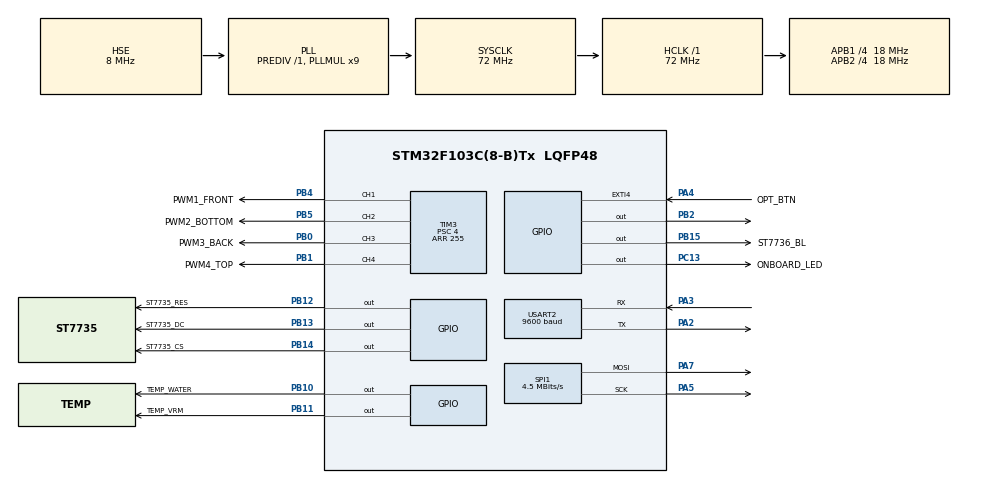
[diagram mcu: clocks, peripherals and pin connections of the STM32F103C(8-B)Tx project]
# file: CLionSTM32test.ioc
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Dma.Request0=SPI1_TX
Dma.SPI1_TX.0.Direction=DMA_MEMORY_TO_PERIPH
Dma.SPI1_TX.0.Instance=DMA1_Channel3
Dma.SPI1_TX.0.MemDataAlignment=DMA_MDATAALIGN_BYTE
Dma.SPI1_TX.0.MemInc=DMA_MINC_ENABLE
Dma.SPI1_TX.0.Mode=DMA_NORMAL
Dma.SPI1_TX.0.PeriphDataAlignment=DMA_PDATAALIGN_BYTE
Dma.SPI1_TX.0.PeriphInc=DMA_PINC_DISABLE
Dma.SPI1_TX.0.Priority=DMA_PRIORITY_LOW
Mcu.Family=STM32F1
Mcu.Name=STM32F103C(8-B)Tx
Mcu.Package=LQFP48
NVIC.DMA1_Channel3_IRQn=true\:0\:0\:false\:false\:true\:false\:true
NVIC.EXTI4_IRQn=true\:0\:0\:false\:false\:true\:true\:true
NVIC.PriorityGroup=NVIC_PRIORITYGROUP_4
NVIC.USART2_IRQn=true\:0\:0\:false\:false\:true\:true\:true
PA13.Mode=Serial_Wire
PA13.Signal=SYS_JTMS-SWDIO
PA14.Mode=Serial_Wire
PA14.Signal=SYS_JTCK-SWCLK
PA2.Mode=Asynchronous
PA2.Signal=USART2_TX
PA3.Mode=Asynchronous
PA3.Signal=USART2_RX
PA4.GPIO_Label=OPT_BTN
PA4.Signal=GPXTI4
PA5.Mode=TX_Only_Simplex_Unidirect_Master
PA5.Signal=SPI1_SCK
PA7.Mode=TX_Only_Simplex_Unidirect_Master
PA7.Signal=SPI1_MOSI
PB0.GPIO_Label=PWM3_BACK
PB0.GPIO_Speed=GPIO_SPEED_FREQ_HIGH
PB0.Signal=S_TIM3_CH3
PB1.GPIO_Label=PWM4_TOP
PB1.GPIO_Speed=GPIO_SPEED_FREQ_HIGH
PB1.Signal=S_TIM3_CH4
PB10.GPIO_Label=TEMP_WATER
PB10.Signal=GPIO_Output
PB11.GPIO_Label=TEMP_VRM
PB11.Signal=GPIO_Output
PB12.GPIO_Label=ST7735_RES
PB12.Signal=GPIO_Output
PB13.GPIO_Label=ST7735_DC
PB13.Signal=GPIO_Output
PB14.GPIO_Label=ST7735_CS
PB14.Signal=GPIO_Output
PB15.GPIO_Label=ST7736_BL
PB15.Signal=GPIO_Output
PB2.Signal=GPIO_Output
PB4.GPIO_Label=PWM1_FRONT
PB4.GPIO_Speed=GPIO_SPEED_FREQ_HIGH
PB4.Signal=S_TIM3_CH1
PB5.GPIO_Label=PWM2_BOTTOM
PB5.GPIO_Speed=GPIO_SPEED_FREQ_HIGH
PB5.Signal=S_TIM3_CH2
PC13-TAMPER-RTC.GPIO_Label=ONBOARD_LED
PC13-TAMPER-RTC.Signal=GPIO_Output
PD0-OSC_IN.Mode=HSE-External-Oscillator
PD0-OSC_IN.Signal=RCC_OSC_IN
PD1-OSC_OUT.Mode=HSE-External-Oscillator
PD1-OSC_OUT.Signal=RCC_OSC_OUT
ProjectManager.HeapSize=0x200
ProjectManager.StackSize=0x400
ProjectManager.TargetToolchain=SW4STM32
RCC.AHBFreq_Value=72000000
RCC.APB1CLKDivider=RCC_HCLK_DIV4
RCC.APB1Freq_Value=18000000
RCC.APB1TimFreq_Value=36000000
RCC.APB2CLKDivider=RCC_HCLK_DIV4
RCC.APB2Freq_Value=18000000
RCC.APB2TimFreq_Value=36000000
RCC.HCLKFreq_Value=72000000
RCC.PLLMUL=RCC_PLL_MUL9
RCC.PLLSourceVirtual=RCC_PLLSOURCE_HSE
RCC.SYSCLKFreq_VALUE=72000000
RCC.SYSCLKSource=RCC_SYSCLKSOURCE_PLLCLK
RCC.USBFreq_Value=72000000
SH.S_TIM3_CH1.0=TIM3_CH1,PWM Generation1 CH1
SH.S_TIM3_CH2.0=TIM3_CH2,PWM Generation2 CH2
SH.S_TIM3_CH3.0=TIM3_CH3,PWM Generation3 CH3
SH.S_TIM3_CH4.0=TIM3_CH4,PWM Generation4 CH4
SPI1.BaudRatePrescaler=SPI_BAUDRATEPRESCALER_4
SPI1.CalculateBaudRate=4.5 MBits/s
SPI1.Direction=SPI_DIRECTION_2LINES
SPI1.Mode=SPI_MODE_MASTER
SPI1.VirtualType=VM_MASTER
TIM3.Channel-PWM\ Generation1\ CH1=TIM_CHANNEL_1
TIM3.Channel-PWM\ Generation2\ CH2=TIM_CHANNEL_2
TIM3.Channel-PWM\ Generation3\ CH3=TIM_CHANNEL_3
TIM3.Channel-PWM\ Generation4\ CH4=TIM_CHANNEL_4
TIM3.Period=255
TIM3.Prescaler=4
USART2.BaudRate=9600
USART2.VirtualMode=VM_ASYNC
VP_TIM3_VS_ClockSourceINT.Mode=Internal
board=custom

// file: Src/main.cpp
/* USER CODE BEGIN Header */
/**
  ******************************************************************************
  * @file           : main.c
  * @brief          : Main program body
  ******************************************************************************
  * @attention
  *
  * <h2><center>&copy; Copyright (c) 2020 STMicroelectronics.
  * All rights reserved.</center></h2>
  *
  * This software component is licensed by ST under BSD 3-Clause license,
  * the "License"; You may not use this file except in compliance with the
  * License. You may obtain a copy of the License at:
  *                        opensource.org/licenses/BSD-3-Clause
  *
  ******************************************************************************
  */
/* USER CODE END Header */

#include "main.h"

/* USER CODE BEGIN Includes */
#include "cpp/Orchestrator.cpp"
/* USER CODE END Includes */

/* USER CODE BEGIN PTD */
#pragma clang diagnostic push
#pragma ide diagnostic ignored "EndlessLoop"
/* USER CODE END PTD */

SPI_HandleTypeDef hspi1;
DMA_HandleTypeDef hdma_spi1_tx;

TIM_HandleTypeDef htim3;

UART_HandleTypeDef huart2;

void SystemClock_Config(void);
static void MX_GPIO_Init(void);
static void MX_DMA_Init(void);
static void MX_SPI1_Init(void);
static void MX_USART2_UART_Init(void);
static void MX_TIM3_Init(void);

int main(void)
{

  /* MCU Configuration--------------------------------------------------------*/

  /* Reset of all peripherals, Initializes the Flash interface and the Systick. */
  HAL_Init();

  /* Configure the system clock */
  SystemClock_Config();

  /* Initialize all configured peripherals */
  MX_GPIO_Init();
  MX_DMA_Init();
  MX_SPI1_Init();
  MX_USART2_UART_Init();
  MX_TIM3_Init();
  /* USER CODE BEGIN 2 */
  HAL_TIM_Base_Start_IT(&htim3); // start timer
  HAL_TIM_PWM_Start(&htim3, TIM_CHANNEL_1);
  HAL_TIM_PWM_Start(&htim3, TIM_CHANNEL_2);
  HAL_TIM_PWM_Start(&htim3, TIM_CHANNEL_3);
  HAL_TIM_PWM_Start(&htim3, TIM_CHANNEL_4);

  Orchestrator orchestrator = Orchestrator(&huart2);
  /* USER CODE END 2 */

  /* Infinite loop */
  /* USER CODE BEGIN WHILE */
  while (true)
  {
    orchestrator.loop();
    /* USER CODE END WHILE */

  }
}

void SystemClock_Config(void)
{
  RCC_OscInitTypeDef RCC_OscInitStruct = {0};
  RCC_ClkInitTypeDef RCC_ClkInitStruct = {0};

  /** Initializes the CPU, AHB and APB busses clocks
  */
  RCC_OscInitStruct.OscillatorType = RCC_OSCILLATORTYPE_HSE;
  RCC_OscInitStruct.HSEState = RCC_HSE_ON;
  RCC_OscInitStruct.HSEPredivValue = RCC_HSE_PREDIV_DIV1;
  RCC_OscInitStruct.HSIState = RCC_HSI_ON;
  RCC_OscInitStruct.PLL.PLLState = RCC_PLL_ON;
  RCC_OscInitStruct.PLL.PLLSource = RCC_PLLSOURCE_HSE;
  RCC_OscInitStruct.PLL.PLLMUL = RCC_PLL_MUL9;
  if (HAL_RCC_OscConfig(&RCC_OscInitStruct) != HAL_OK)
  {
    Error_Handler();
  }
  /** Initializes the CPU, AHB and APB busses clocks
  */
  RCC_ClkInitStruct.ClockType = RCC_CLOCKTYPE_HCLK|RCC_CLOCKTYPE_SYSCLK
                              |RCC_CLOCKTYPE_PCLK1|RCC_CLOCKTYPE_PCLK2;
  RCC_ClkInitStruct.SYSCLKSource = RCC_SYSCLKSOURCE_PLLCLK;
  RCC_ClkInitStruct.AHBCLKDivider = RCC_SYSCLK_DIV1;
  RCC_ClkInitStruct.APB1CLKDivider = RCC_HCLK_DIV4;
  RCC_ClkInitStruct.APB2CLKDivider = RCC_HCLK_DIV4;

  if (HAL_RCC_ClockConfig(&RCC_ClkInitStruct, FLASH_LATENCY_2) != HAL_OK)
  {
    Error_Handler();
  }
}

static void MX_SPI1_Init(void)
{

  /* SPI1 parameter configuration*/
  hspi1.Instance = SPI1;
  hspi1.Init.Mode = SPI_MODE_MASTER;
  hspi1.Init.Direction = SPI_DIRECTION_2LINES;
  hspi1.Init.DataSize = SPI_DATASIZE_8BIT;
  hspi1.Init.CLKPolarity = SPI_POLARITY_LOW;
  hspi1.Init.CLKPhase = SPI_PHASE_1EDGE;
  hspi1.Init.NSS = SPI_NSS_SOFT;
  hspi1.Init.BaudRatePrescaler = SPI_BAUDRATEPRESCALER_4;
  hspi1.Init.FirstBit = SPI_FIRSTBIT_MSB;
  hspi1.Init.TIMode = SPI_TIMODE_DISABLE;
  hspi1.Init.CRCCalculation = SPI_CRCCALCULATION_DISABLE;
  hspi1.Init.CRCPolynomial = 10;
  if (HAL_SPI_Init(&hspi1) != HAL_OK)
  {
    Error_Handler();
  }

}

static void MX_TIM3_Init(void)
{

  TIM_ClockConfigTypeDef sClockSourceConfig = {0};
  TIM_MasterConfigTypeDef sMasterConfig = {0};
  TIM_OC_InitTypeDef sConfigOC = {0};

  htim3.Instance = TIM3;
  htim3.Init.Prescaler = 4;
  htim3.Init.CounterMode = TIM_COUNTERMODE_UP;
  htim3.Init.Period = 255;
  htim3.Init.ClockDivision = TIM_CLOCKDIVISION_DIV1;
  htim3.Init.AutoReloadPreload = TIM_AUTORELOAD_PRELOAD_DISABLE;
  if (HAL_TIM_Base_Init(&htim3) != HAL_OK)
  {
    Error_Handler();
  }
  sClockSourceConfig.ClockSource = TIM_CLOCKSOURCE_INTERNAL;
  if (HAL_TIM_ConfigClockSource(&htim3, &sClockSourceConfig) != HAL_OK)
  {
    Error_Handler();
  }
  if (HAL_TIM_PWM_Init(&htim3) != HAL_OK)
  {
    Error_Handler();
  }
  sMasterConfig.MasterOutputTrigger = TIM_TRGO_RESET;
  sMasterConfig.MasterSlaveMode = TIM_MASTERSLAVEMODE_DISABLE;
  if (HAL_TIMEx_MasterConfigSynchronization(&htim3, &sMasterConfig) != HAL_OK)
  {
    Error_Handler();
  }
  sConfigOC.OCMode = TIM_OCMODE_PWM1;
  sConfigOC.Pulse = 0;
  sConfigOC.OCPolarity = TIM_OCPOLARITY_HIGH;
  sConfigOC.OCFastMode = TIM_OCFAST_DISABLE;
  if (HAL_TIM_PWM_ConfigChannel(&htim3, &sConfigOC, TIM_CHANNEL_1) != HAL_OK)
  {
    Error_Handler();
  }
  if (HAL_TIM_PWM_ConfigChannel(&htim3, &sConfigOC, TIM_CHANNEL_2) != HAL_OK)
  {
    Error_Handler();
  }
  if (HAL_TIM_PWM_ConfigChannel(&htim3, &sConfigOC, TIM_CHANNEL_3) != HAL_OK)
  {
    Error_Handler();
  }
  if (HAL_TIM_PWM_ConfigChannel(&htim3, &sConfigOC, TIM_CHANNEL_4) != HAL_OK)
  {
    Error_Handler();
  }
  HAL_TIM_MspPostInit(&htim3);

}

static void MX_USART2_UART_Init(void)
{

  huart2.Instance = USART2;
  huart2.Init.BaudRate = 9600;
  huart2.Init.WordLength = UART_WORDLENGTH_8B;
  huart2.Init.StopBits = UART_STOPBITS_1;
  huart2.Init.Parity = UART_PARITY_NONE;
  huart2.Init.Mode = UART_MODE_TX_RX;
  huart2.Init.HwFlowCtl = UART_HWCONTROL_NONE;
  huart2.Init.OverSampling = UART_OVERSAMPLING_16;
  if (HAL_UART_Init(&huart2) != HAL_OK)
  {
    Error_Handler();
  }

}

static void MX_DMA_Init(void)
{

  /* DMA controller clock enable */
  __HAL_RCC_DMA1_CLK_ENABLE();

  /* DMA interrupt init */
  /* DMA1_Channel3_IRQn interrupt configuration */
  HAL_NVIC_SetPriority(DMA1_Channel3_IRQn, 0, 0);
  HAL_NVIC_EnableIRQ(DMA1_Channel3_IRQn);

}

static void MX_GPIO_Init(void)
{
  GPIO_InitTypeDef GPIO_InitStruct = {0};

  /* GPIO Ports Clock Enable */
  __HAL_RCC_GPIOC_CLK_ENABLE();
  __HAL_RCC_GPIOD_CLK_ENABLE();
  __HAL_RCC_GPIOA_CLK_ENABLE();
  __HAL_RCC_GPIOB_CLK_ENABLE();

  /*Configure GPIO pin Output Level */
  HAL_GPIO_WritePin(ONBOARD_LED_GPIO_Port, ONBOARD_LED_Pin, GPIO_PIN_RESET);

  /*Configure GPIO pin Output Level */
  HAL_GPIO_WritePin(GPIOB, GPIO_PIN_2|TEMP_WATER_Pin|TEMP_VRM_Pin|ST7735_RES_Pin
                          |ST7735_DC_Pin|ST7735_CS_Pin|ST7736_BL_Pin, GPIO_PIN_RESET);

  /*Configure GPIO pin : ONBOARD_LED_Pin */
  GPIO_InitStruct.Pin = ONBOARD_LED_Pin;
  GPIO_InitStruct.Mode = GPIO_MODE_OUTPUT_PP;
  GPIO_InitStruct.Pull = GPIO_NOPULL;
  GPIO_InitStruct.Speed = GPIO_SPEED_FREQ_LOW;
  HAL_GPIO_Init(ONBOARD_LED_GPIO_Port, &GPIO_InitStruct);

  /*Configure GPIO pin : OPT_BTN_Pin */
  GPIO_InitStruct.Pin = OPT_BTN_Pin;
  GPIO_InitStruct.Mode = GPIO_MODE_IT_RISING;
  GPIO_InitStruct.Pull = GPIO_NOPULL;
  HAL_GPIO_Init(OPT_BTN_GPIO_Port, &GPIO_InitStruct);

  /*Configure GPIO pins : PB2 TEMP_WATER_Pin TEMP_VRM_Pin ST7735_RES_Pin
                           ST7735_DC_Pin ST7735_CS_Pin ST7736_BL_Pin */
  GPIO_InitStruct.Pin = GPIO_PIN_2|TEMP_WATER_Pin|TEMP_VRM_Pin|ST7735_RES_Pin
                          |ST7735_DC_Pin|ST7735_CS_Pin|ST7736_BL_Pin;
  GPIO_InitStruct.Mode = GPIO_MODE_OUTPUT_PP;
  GPIO_InitStruct.Pull = GPIO_NOPULL;
  GPIO_InitStruct.Speed = GPIO_SPEED_FREQ_LOW;
  HAL_GPIO_Init(GPIOB, &GPIO_InitStruct);

  /* EXTI interrupt init*/
  HAL_NVIC_SetPriority(EXTI4_IRQn, 0, 0);
  HAL_NVIC_EnableIRQ(EXTI4_IRQn);

}

void Error_Handler(void)
{
}

/************************ (C) COPYRIGHT STMicroelectronics *****END OF FILE****/
